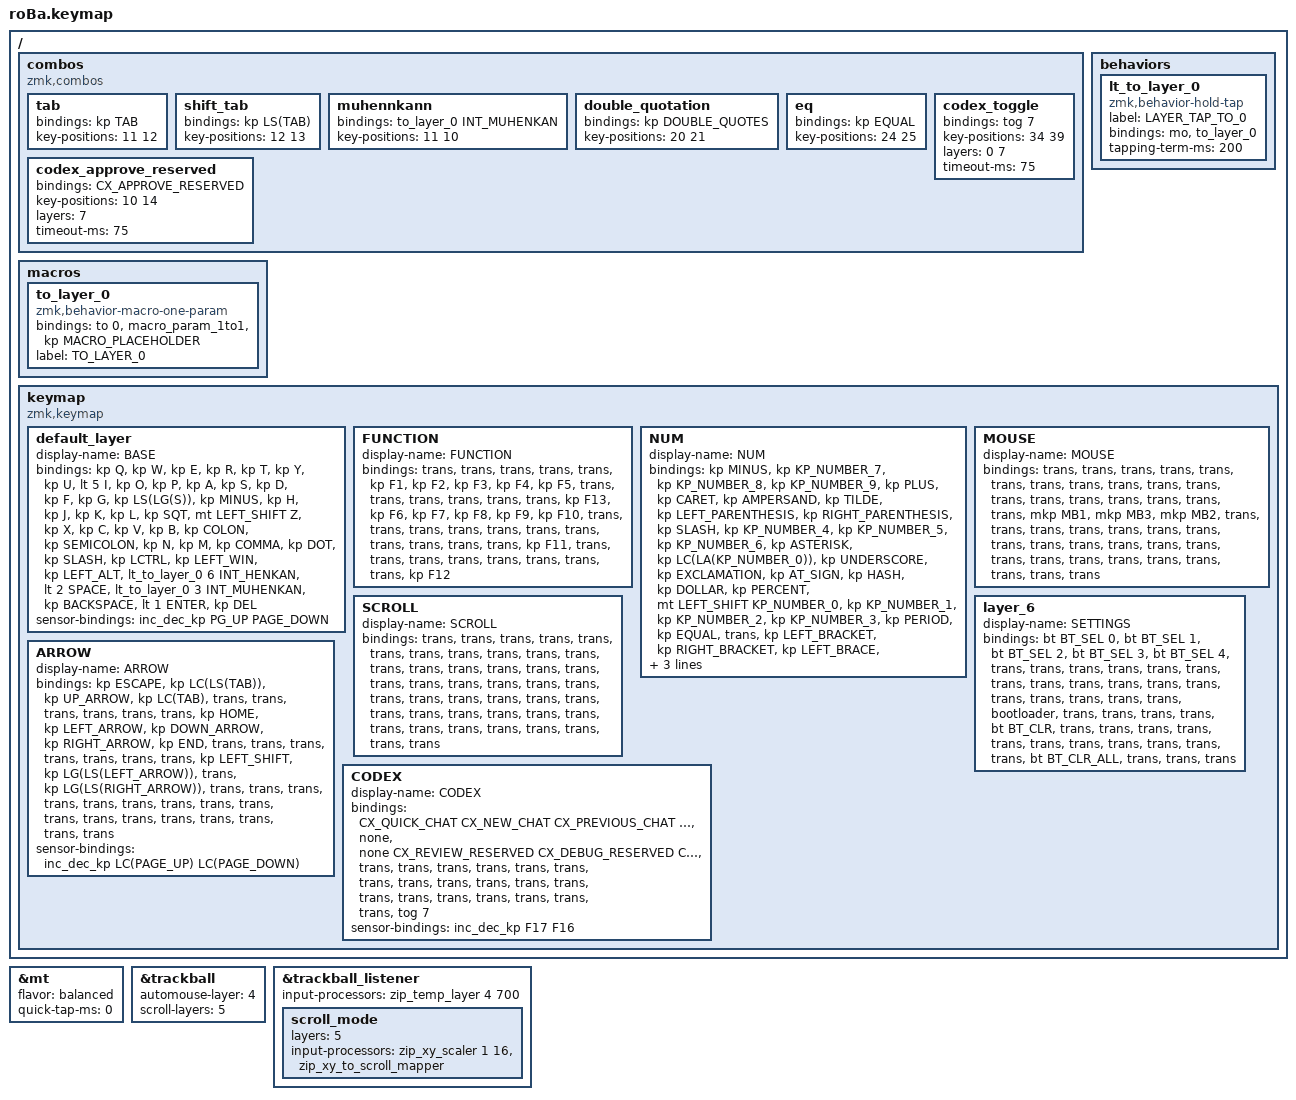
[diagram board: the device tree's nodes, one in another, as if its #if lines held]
#include <behaviors.dtsi>
#include <dt-bindings/zmk/bt.h>
#include <dt-bindings/zmk/keys.h>
#include <dt-bindings/zmk/pointing.h>
#include <input/processors.dtsi>
#include "codex_shortcuts.h"

&mt {
    flavor = "balanced";
    quick-tap-ms = <0>;
};

#if defined(CONFIG_SHIELD_ROBA_R)
&trackball {
    automouse-layer = <4>;
    scroll-layers = <5>;

    // arrows {
    //     layers = <3>;
    //     bindings =
    //         <&kp RIGHT_ARROW>,
    //         <&kp LEFT_ARROW>,
    //         <&kp UP_ARROW>,
    //         <&kp DOWN_ARROW>;

    //     tick = <10>;
    //     wait-ms = <5>;
    //     tap-ms = <5>;
    // };
};
#endif

#if defined(CONFIG_SHIELD_ROBA_DONGLE)
&trackball_listener {
    input-processors = <&zip_temp_layer 4 700>;

    scroll_mode {
        layers = <5>;
        input-processors = <&zip_xy_scaler 1 16>, <&zip_xy_to_scroll_mapper>;
    };
};
#endif

/ {
    combos {
        compatible = "zmk,combos";

        tab {
            bindings = <&kp TAB>;
            key-positions = <11 12>;
        };

        shift_tab {
            bindings = <&kp LS(TAB)>;
            key-positions = <12 13>;
        };

        muhennkann {
            bindings = <&to_layer_0 INT_MUHENKAN>;
            key-positions = <11 10>;
        };

        double_quotation {
            bindings = <&kp DOUBLE_QUOTES>;
            key-positions = <20 21>;
        };

        eq {
            bindings = <&kp EQUAL>;
            key-positions = <24 25>;
        };

#if defined(ROBA_CODEX_LEFT_STANDALONE)
        codex_toggle {
            bindings = <&tog 7>;
            key-positions = <34 39>;
            layers = <0 7>;
            timeout-ms = <75>;
        };

        codex_approve_reserved {
            bindings = <CX_APPROVE_RESERVED>;
            key-positions = <10 14>;
            layers = <7>;
            timeout-ms = <75>;
        };
#else
        codex_toggle {
            bindings = <&tog 7>;
            key-positions = <35 42>;
            layers = <0 7>;
            timeout-ms = <75>;
        };

        codex_approve_reserved {
            bindings = <CX_APPROVE_RESERVED>;
            key-positions = <15 16>;
            layers = <7>;
            timeout-ms = <75>;
        };
#endif
    };

    macros {
        to_layer_0: to_layer_0 {
            compatible = "zmk,behavior-macro-one-param";
            #binding-cells = <1>;
            bindings = <&to 0 &macro_param_1to1 &kp MACRO_PLACEHOLDER>;
            label = "TO_LAYER_0";
        };
    };

    behaviors {
        lt_to_layer_0: lt_to_layer_0 {
            compatible = "zmk,behavior-hold-tap";
            label = "LAYER_TAP_TO_0";
            bindings = <&mo>, <&to_layer_0>;

            #binding-cells = <2>;
            tapping-term-ms = <200>;
        };
    };

    keymap {
        compatible = "zmk,keymap";

        default_layer {
            display-name = "BASE";
            bindings = <
&kp Q             &kp W         &kp E         &kp R                        &kp T                                                          &kp Y        &kp U  &lt 5 I    &kp O    &kp P
&kp A             &kp S         &kp D         &kp F                        &kp G        &kp LS(LG(S))                      &kp MINUS      &kp H        &kp J  &kp K      &kp L    &kp SQT
&mt LEFT_SHIFT Z  &kp X         &kp C         &kp V                        &kp B        &kp COLON                          &kp SEMICOLON  &kp N        &kp M  &kp COMMA  &kp DOT  &kp SLASH
&kp LCTRL         &kp LEFT_WIN  &kp LEFT_ALT  &lt_to_layer_0 6 INT_HENKAN  &lt 2 SPACE  &lt_to_layer_0 3 INT_MUHENKAN      &kp BACKSPACE  &lt 1 ENTER                             &kp DEL
            >;

            sensor-bindings = <&inc_dec_kp PG_UP PAGE_DOWN>;
        };

        FUNCTION {
            display-name = "FUNCTION";
            bindings = <
&trans  &trans  &trans  &trans  &trans                       &kp F1  &kp F2  &kp F3  &kp F4  &kp F5
&trans  &trans  &trans  &trans  &trans  &trans      &kp F13  &kp F6  &kp F7  &kp F8  &kp F9  &kp F10
&trans  &trans  &trans  &trans  &trans  &trans      &trans   &trans  &trans  &trans  &trans  &kp F11
&trans  &trans  &trans  &trans  &trans  &trans      &trans   &trans                          &kp F12
            >;
        };

        NUM {
            display-name = "NUM";
            bindings = <
&kp MINUS                   &kp KP_NUMBER_7  &kp KP_NUMBER_8  &kp KP_NUMBER_9  &kp PLUS                                                   &kp CARET         &kp AMPERSAND      &kp TILDE       &kp LEFT_PARENTHESIS  &kp RIGHT_PARENTHESIS
&kp SLASH                   &kp KP_NUMBER_4  &kp KP_NUMBER_5  &kp KP_NUMBER_6  &kp ASTERISK  &kp LC(LA(KP_NUMBER_0))      &kp UNDERSCORE  &kp EXCLAMATION   &kp AT_SIGN        &kp HASH        &kp DOLLAR            &kp PERCENT
&mt LEFT_SHIFT KP_NUMBER_0  &kp KP_NUMBER_1  &kp KP_NUMBER_2  &kp KP_NUMBER_3  &kp PERIOD    &kp EQUAL                    &trans          &kp LEFT_BRACKET  &kp RIGHT_BRACKET  &kp LEFT_BRACE  &kp RIGHT_BRACE       &kp BACKSLASH
&trans                      &trans           &trans           &trans           &trans        &trans                       &trans          &trans                                                                     &kp PIPE
            >;
        };

        ARROW {
            display-name = "ARROW";
            bindings = <
&kp ESCAPE      &kp LC(LS(TAB))         &kp UP_ARROW    &kp LC(TAB)              &trans                       &trans  &trans  &trans  &trans  &trans
&kp HOME        &kp LEFT_ARROW          &kp DOWN_ARROW  &kp RIGHT_ARROW          &kp END  &trans      &trans  &trans  &trans  &trans  &trans  &trans
&kp LEFT_SHIFT  &kp LG(LS(LEFT_ARROW))  &trans          &kp LG(LS(RIGHT_ARROW))  &trans   &trans      &trans  &trans  &trans  &trans  &trans  &trans
&trans          &trans                  &trans          &trans                   &trans   &trans      &trans  &trans                          &trans
            >;

            sensor-bindings = <&inc_dec_kp LC(PAGE_UP) LC(PAGE_DOWN)>;
        };

        MOUSE {
            display-name = "MOUSE";
            bindings = <
&trans  &trans  &trans  &trans  &trans                      &trans  &trans    &trans    &trans    &trans
&trans  &trans  &trans  &trans  &trans  &trans      &trans  &trans  &mkp MB1  &mkp MB3  &mkp MB2  &trans
&trans  &trans  &trans  &trans  &trans  &trans      &trans  &trans  &trans    &trans    &trans    &trans
&trans  &trans  &trans  &trans  &trans  &trans      &trans  &trans                                &trans
            >;
        };

        SCROLL {
            display-name = "SCROLL";
            bindings = <
&trans  &trans  &trans  &trans  &trans                      &trans  &trans  &trans  &trans  &trans
&trans  &trans  &trans  &trans  &trans  &trans      &trans  &trans  &trans  &trans  &trans  &trans
&trans  &trans  &trans  &trans  &trans  &trans      &trans  &trans  &trans  &trans  &trans  &trans
&trans  &trans  &trans  &trans  &trans  &trans      &trans  &trans                          &trans
            >;
        };

        layer_6 {
            display-name = "SETTINGS";
#if defined(ROBA_CODEX_LEFT_STANDALONE)
            bindings = <
&bt BT_SEL 0  &bt BT_SEL 1  &bt BT_SEL 2  &bt BT_SEL 3  &bt BT_SEL 4                      &trans  &trans  &trans  &trans  &trans
&trans        &trans        &trans        &trans        &trans  &trans      &trans       &trans  &trans  &trans  &trans  &trans
&bootloader   &trans        &trans        &trans        &trans  &bt BT_CLR  &trans       &trans  &trans  &trans  &trans  &trans
&trans        &trans        &trans        &trans        &trans  &bt BT_CLR_ALL            &trans  &trans          &trans
            >;
#else
            bindings = <
&trans  &trans        &trans        &trans        &trans                           &bt BT_SEL 0  &bt BT_SEL 1  &bt BT_SEL 2  &bt BT_SEL 3  &bt BT_SEL 4
&trans  &trans        &trans        &trans        &trans  &trans      &trans       &trans        &trans        &trans        &trans        &trans
&trans  &kp NUMBER_1  &kp NUMBER_2  &kp NUMBER_3  &trans  &trans      &bootloader  &trans        &trans        &trans        &trans        &bt BT_CLR
&trans  &trans        &trans        &trans        &trans  &trans      &trans       &trans                                                  &bt BT_CLR_ALL
            >;
#endif
        };

        CODEX {
            display-name = "CODEX";
            bindings = <
CX_QUICK_CHAT        CX_NEW_CHAT       CX_PREVIOUS_CHAT       CX_NEXT_CHAT             CX_COMMAND_MENU                                             CX_REVIEW_TAB         CX_SETTINGS          CX_REASON_DOWN_RESERVED  CX_REASON_UP_RESERVED  CX_DICTATION
CX_SEARCH_CHATS      CX_SEND           CX_INTERRUPT_RESERVED  CX_FOCUS_RESERVED        CX_VOICE_RESERVED  &none      &none                   CX_REVIEW_RESERVED    CX_DEBUG_RESERVED    CX_REFACTOR_RESERVED   CX_AGENT_PREV_RESERVED  CX_AGENT_NEXT_RESERVED
CX_DECLINE_RESERVED  &trans            &trans                  &trans                    &trans              &trans     &trans                  &trans                &trans                &trans                  &trans                   &trans
&trans               &trans            &trans                  &trans                    &trans              &trans     &trans                  &trans                                                                 &tog 7
            >;

            sensor-bindings = <&inc_dec_kp F17 F16>;
        };
    };
};
